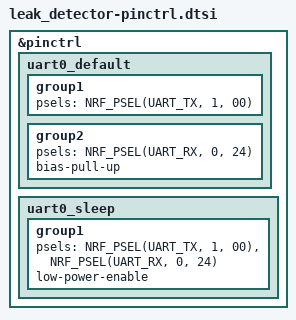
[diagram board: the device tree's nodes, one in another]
&pinctrl {
	uart0_default: uart0_default {
		group1 {
			psels = <NRF_PSEL(UART_TX, 1, 00)>;
		};
		group2 {
			psels = <NRF_PSEL(UART_RX, 0, 24)>;
			bias-pull-up;
		};
	};

	uart0_sleep: uart0_sleep {
		group1 {
			psels = <NRF_PSEL(UART_TX, 1, 00)>,
				<NRF_PSEL(UART_RX, 0, 24)>;
			low-power-enable;
		};
	};
};
